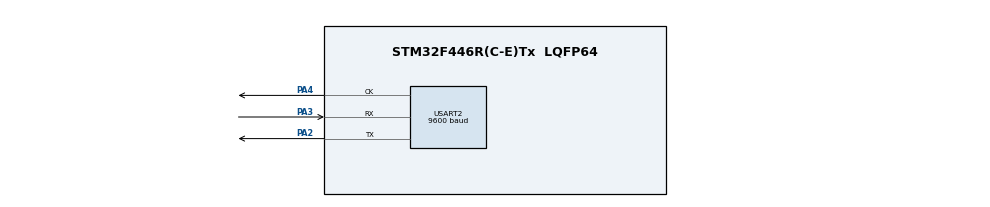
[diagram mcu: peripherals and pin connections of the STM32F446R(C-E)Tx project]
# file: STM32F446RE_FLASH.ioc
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Mcu.Family=STM32F4
Mcu.Name=STM32F446R(C-E)Tx
Mcu.Package=LQFP64
NVIC.PriorityGroup=NVIC_PRIORITYGROUP_4
PA13.Mode=Serial_Wire
PA13.Signal=SYS_JTMS-SWDIO
PA14.Mode=Serial_Wire
PA14.Signal=SYS_JTCK-SWCLK
PA2.Mode=Synchronous
PA2.Signal=USART2_TX
PA3.Mode=Synchronous
PA3.Signal=USART2_RX
PA4.Mode=Synchronous
PA4.Signal=USART2_CK
PH0-OSC_IN.Mode=HSE-External-Oscillator
PH0-OSC_IN.Signal=RCC_OSC_IN
PH1-OSC_OUT.Mode=HSE-External-Oscillator
PH1-OSC_OUT.Signal=RCC_OSC_OUT
ProjectManager.HeapSize=0x200
ProjectManager.StackSize=0x400
ProjectManager.TargetToolchain=STM32CubeIDE
RCC.CortexFreq_Value=16000000
RCC.USBFreq_Value=96000000
RCC.VCOOutputFreq_Value=192000000
USART2.BaudRate=9600
USART2.VirtualMode=VM_SYNC
board=custom

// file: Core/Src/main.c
/* USER CODE BEGIN Header */
/**
  ******************************************************************************
  * @file           : main.c
  * @brief          : Main program body
  ******************************************************************************
  * @attention
  *
  * Copyright (c) 2022 STMicroelectronics.
  * All rights reserved.
  *
  * This software is licensed under terms that can be found in the LICENSE file
  * in the root directory of this software component.
  * If no LICENSE file comes with this software, it is provided AS-IS.
  *
  ******************************************************************************
  */
/* USER CODE END Header */
#include "main.h"
#include "usart.h"
#include "gpio.h"

/* USER CODE BEGIN Includes */
#include "ee.h"
/* USER CODE END Includes */

void SystemClock_Config(void);

int main(void)
{

  /* MCU Configuration--------------------------------------------------------*/

  /* Reset of all peripherals, Initializes the Flash interface and the Systick. */
  HAL_Init();

  /* Configure the system clock */
  SystemClock_Config();

  /* Initialize all configured peripherals */
  MX_GPIO_Init();
  MX_USART2_Init();
  /* USER CODE BEGIN 2 */
  ee_init();
  static uint8_t dataToWrite[4] = {1, 2, 3, 4};
  static uint8_t dataRead[4];
  ee_write(0, 4, dataToWrite);
  ee_read(0, 4, dataRead);

  /* USER CODE END 2 */

  /* Infinite loop */
  while (1)
  {

    /* USER CODE BEGIN 3 */
		char buffer[100];
		sprintf(buffer, "%d, %d, %d, %d", dataRead[0], dataRead[1], dataRead[2], dataRead[3]);
		HAL_USART_Transmit(&husart2, buffer, strlen(buffer), 1000);
		HAL_Delay(1000);
  }
  /* USER CODE END 3 */
}

void SystemClock_Config(void)
{
  RCC_OscInitTypeDef RCC_OscInitStruct = {0};
  RCC_ClkInitTypeDef RCC_ClkInitStruct = {0};

  /** Configure the main internal regulator output voltage
  */
  __HAL_RCC_PWR_CLK_ENABLE();
  __HAL_PWR_VOLTAGESCALING_CONFIG(PWR_REGULATOR_VOLTAGE_SCALE3);
  /** Initializes the RCC Oscillators according to the specified parameters
  * in the RCC_OscInitTypeDef structure.
  */
  RCC_OscInitStruct.OscillatorType = RCC_OSCILLATORTYPE_HSI;
  RCC_OscInitStruct.HSIState = RCC_HSI_ON;
  RCC_OscInitStruct.HSICalibrationValue = RCC_HSICALIBRATION_DEFAULT;
  RCC_OscInitStruct.PLL.PLLState = RCC_PLL_NONE;
  if (HAL_RCC_OscConfig(&RCC_OscInitStruct) != HAL_OK)
  {
    Error_Handler();
  }
  /** Initializes the CPU, AHB and APB buses clocks
  */
  RCC_ClkInitStruct.ClockType = RCC_CLOCKTYPE_HCLK|RCC_CLOCKTYPE_SYSCLK
                              |RCC_CLOCKTYPE_PCLK1|RCC_CLOCKTYPE_PCLK2;
  RCC_ClkInitStruct.SYSCLKSource = RCC_SYSCLKSOURCE_HSI;
  RCC_ClkInitStruct.AHBCLKDivider = RCC_SYSCLK_DIV1;
  RCC_ClkInitStruct.APB1CLKDivider = RCC_HCLK_DIV1;
  RCC_ClkInitStruct.APB2CLKDivider = RCC_HCLK_DIV1;

  if (HAL_RCC_ClockConfig(&RCC_ClkInitStruct, FLASH_LATENCY_0) != HAL_OK)
  {
    Error_Handler();
  }
}

void Error_Handler(void)
{
  __disable_irq();
  while (1)
  {
  }
}
